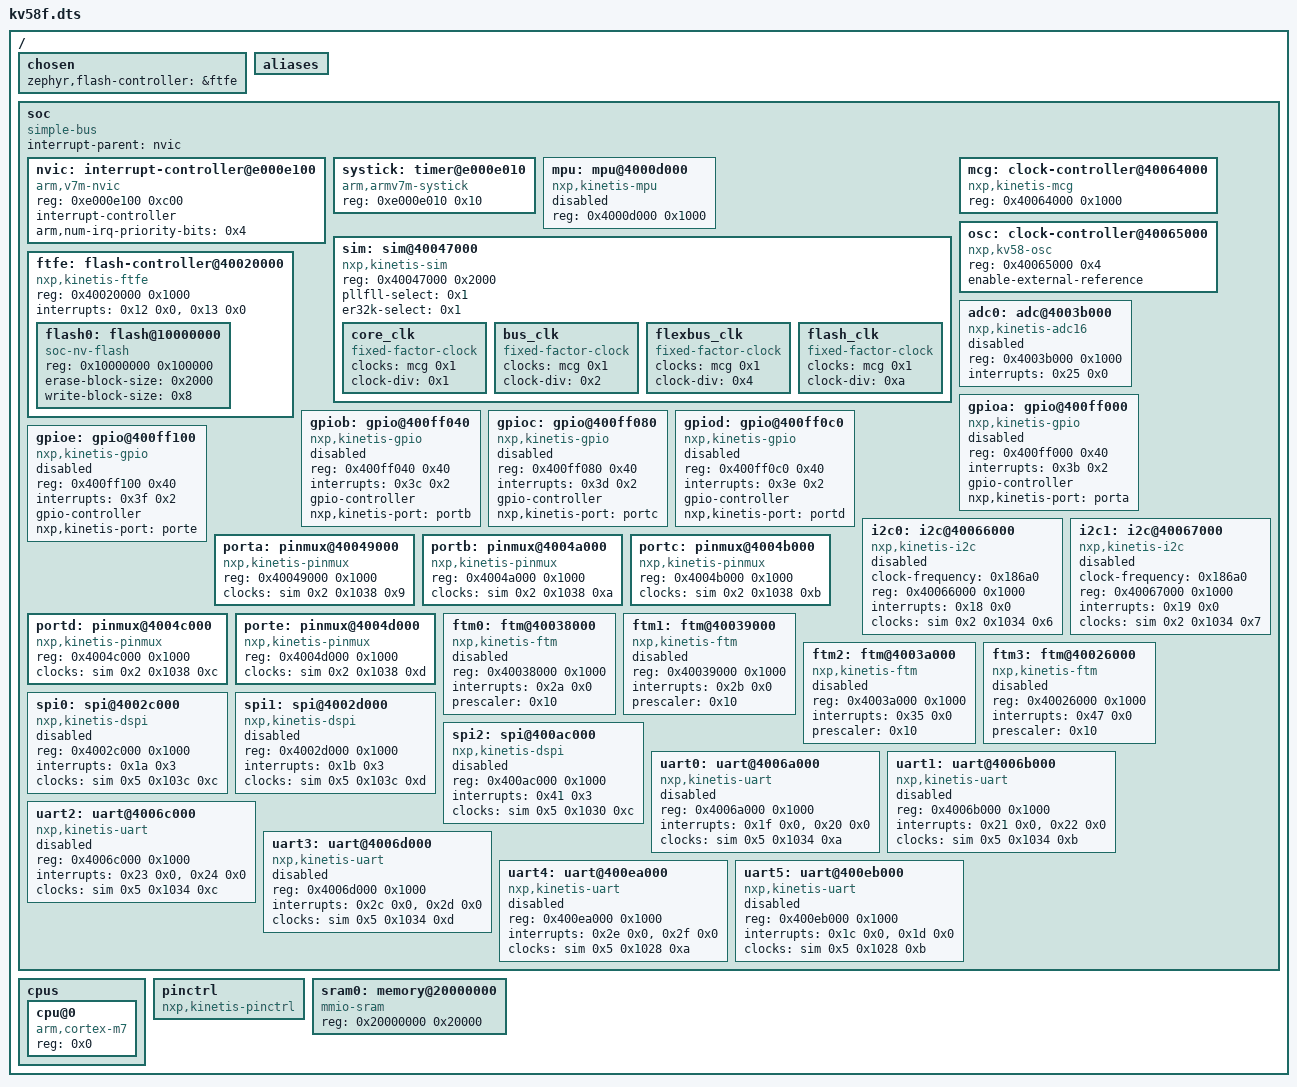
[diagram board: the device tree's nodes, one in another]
/dts-v1/;

/ {
	#address-cells = < 0x1 >;
	#size-cells = < 0x1 >;
	chosen {
		zephyr,flash-controller = &ftfe;
	};
	aliases {
	};
	soc {
		#address-cells = < 0x1 >;
		#size-cells = < 0x1 >;
		compatible = "simple-bus";
		interrupt-parent = < &nvic >;
		ranges;
		nvic: interrupt-controller@e000e100 {
			#address-cells = < 0x1 >;
			compatible = "arm,v7m-nvic";
			reg = < 0xe000e100 0xc00 >;
			interrupt-controller;
			#interrupt-cells = < 0x2 >;
			arm,num-irq-priority-bits = < 0x4 >;
			phandle = < 0x1 >;
		};
		systick: timer@e000e010 {
			compatible = "arm,armv7m-systick";
			reg = < 0xe000e010 0x10 >;
		};
		mpu: mpu@4000d000 {
			compatible = "nxp,kinetis-mpu";
			reg = < 0x4000d000 0x1000 >;
			status = "disabled";
		};
		sim: sim@40047000 {
			compatible = "nxp,kinetis-sim";
			reg = < 0x40047000 0x2000 >;
			#clock-cells = < 0x3 >;
			pllfll-select = < 0x1 >;
			er32k-select = < 0x1 >;
			phandle = < 0x8 >;
			core_clk {
				compatible = "fixed-factor-clock";
				clocks = < &mcg 0x1 >;
				clock-div = < 0x1 >;
				#clock-cells = < 0x0 >;
			};
			bus_clk {
				compatible = "fixed-factor-clock";
				clocks = < &mcg 0x1 >;
				clock-div = < 0x2 >;
				#clock-cells = < 0x0 >;
			};
			flexbus_clk {
				compatible = "fixed-factor-clock";
				clocks = < &mcg 0x1 >;
				clock-div = < 0x4 >;
				#clock-cells = < 0x0 >;
			};
			flash_clk {
				compatible = "fixed-factor-clock";
				clocks = < &mcg 0x1 >;
				clock-div = < 0xa >;
				#clock-cells = < 0x0 >;
			};
		};
		mcg: clock-controller@40064000 {
			compatible = "nxp,kinetis-mcg";
			reg = < 0x40064000 0x1000 >;
			#clock-cells = < 0x1 >;
			phandle = < 0x2 >;
		};
		osc: clock-controller@40065000 {
			compatible = "nxp,kv58-osc";
			reg = < 0x40065000 0x4 >;
			enable-external-reference;
		};
		ftfe: flash-controller@40020000 {
			compatible = "nxp,kinetis-ftfe";
			reg = < 0x40020000 0x1000 >;
			interrupts = < 0x12 0x0 >, < 0x13 0x0 >;
			interrupt-names = "command-complete", "read-collision";
			#address-cells = < 0x1 >;
			#size-cells = < 0x1 >;
			flash0: flash@10000000 {
				compatible = "soc-nv-flash";
				reg = < 0x10000000 0x100000 >;
				erase-block-size = < 0x2000 >;
				write-block-size = < 0x8 >;
			};
		};
		adc0: adc@4003b000 {
			compatible = "nxp,kinetis-adc16";
			reg = < 0x4003b000 0x1000 >;
			interrupts = < 0x25 0x0 >;
			status = "disabled";
			#io-channel-cells = < 0x1 >;
		};
		gpioa: gpio@400ff000 {
			compatible = "nxp,kinetis-gpio";
			status = "disabled";
			reg = < 0x400ff000 0x40 >;
			interrupts = < 0x3b 0x2 >;
			gpio-controller;
			#gpio-cells = < 0x2 >;
			nxp,kinetis-port = < &porta >;
		};
		gpiob: gpio@400ff040 {
			compatible = "nxp,kinetis-gpio";
			status = "disabled";
			reg = < 0x400ff040 0x40 >;
			interrupts = < 0x3c 0x2 >;
			gpio-controller;
			#gpio-cells = < 0x2 >;
			nxp,kinetis-port = < &portb >;
		};
		gpioc: gpio@400ff080 {
			compatible = "nxp,kinetis-gpio";
			status = "disabled";
			reg = < 0x400ff080 0x40 >;
			interrupts = < 0x3d 0x2 >;
			gpio-controller;
			#gpio-cells = < 0x2 >;
			nxp,kinetis-port = < &portc >;
		};
		gpiod: gpio@400ff0c0 {
			compatible = "nxp,kinetis-gpio";
			status = "disabled";
			reg = < 0x400ff0c0 0x40 >;
			interrupts = < 0x3e 0x2 >;
			gpio-controller;
			#gpio-cells = < 0x2 >;
			nxp,kinetis-port = < &portd >;
		};
		gpioe: gpio@400ff100 {
			compatible = "nxp,kinetis-gpio";
			status = "disabled";
			reg = < 0x400ff100 0x40 >;
			interrupts = < 0x3f 0x2 >;
			gpio-controller;
			#gpio-cells = < 0x2 >;
			nxp,kinetis-port = < &porte >;
		};
		i2c0: i2c@40066000 {
			compatible = "nxp,kinetis-i2c";
			clock-frequency = < 0x186a0 >;
			#address-cells = < 0x1 >;
			#size-cells = < 0x0 >;
			reg = < 0x40066000 0x1000 >;
			interrupts = < 0x18 0x0 >;
			clocks = < &sim 0x2 0x1034 0x6 >;
			status = "disabled";
		};
		i2c1: i2c@40067000 {
			compatible = "nxp,kinetis-i2c";
			clock-frequency = < 0x186a0 >;
			#address-cells = < 0x1 >;
			#size-cells = < 0x0 >;
			reg = < 0x40067000 0x1000 >;
			interrupts = < 0x19 0x0 >;
			clocks = < &sim 0x2 0x1034 0x7 >;
			status = "disabled";
		};
		porta: pinmux@40049000 {
			compatible = "nxp,kinetis-pinmux";
			reg = < 0x40049000 0x1000 >;
			clocks = < &sim 0x2 0x1038 0x9 >;
			phandle = < 0x3 >;
		};
		portb: pinmux@4004a000 {
			compatible = "nxp,kinetis-pinmux";
			reg = < 0x4004a000 0x1000 >;
			clocks = < &sim 0x2 0x1038 0xa >;
			phandle = < 0x4 >;
		};
		portc: pinmux@4004b000 {
			compatible = "nxp,kinetis-pinmux";
			reg = < 0x4004b000 0x1000 >;
			clocks = < &sim 0x2 0x1038 0xb >;
			phandle = < 0x5 >;
		};
		portd: pinmux@4004c000 {
			compatible = "nxp,kinetis-pinmux";
			reg = < 0x4004c000 0x1000 >;
			clocks = < &sim 0x2 0x1038 0xc >;
			phandle = < 0x6 >;
		};
		porte: pinmux@4004d000 {
			compatible = "nxp,kinetis-pinmux";
			reg = < 0x4004d000 0x1000 >;
			clocks = < &sim 0x2 0x1038 0xd >;
			phandle = < 0x7 >;
		};
		ftm0: ftm@40038000 {
			compatible = "nxp,kinetis-ftm";
			reg = < 0x40038000 0x1000 >;
			interrupts = < 0x2a 0x0 >;
			prescaler = < 0x10 >;
			status = "disabled";
		};
		ftm1: ftm@40039000 {
			compatible = "nxp,kinetis-ftm";
			reg = < 0x40039000 0x1000 >;
			interrupts = < 0x2b 0x0 >;
			prescaler = < 0x10 >;
			status = "disabled";
		};
		ftm2: ftm@4003a000 {
			compatible = "nxp,kinetis-ftm";
			reg = < 0x4003a000 0x1000 >;
			interrupts = < 0x35 0x0 >;
			prescaler = < 0x10 >;
			status = "disabled";
		};
		ftm3: ftm@40026000 {
			compatible = "nxp,kinetis-ftm";
			reg = < 0x40026000 0x1000 >;
			interrupts = < 0x47 0x0 >;
			prescaler = < 0x10 >;
			status = "disabled";
		};
		spi0: spi@4002c000 {
			compatible = "nxp,kinetis-dspi";
			reg = < 0x4002c000 0x1000 >;
			interrupts = < 0x1a 0x3 >;
			status = "disabled";
			clocks = < &sim 0x5 0x103c 0xc >;
			#address-cells = < 0x1 >;
			#size-cells = < 0x0 >;
		};
		spi1: spi@4002d000 {
			compatible = "nxp,kinetis-dspi";
			reg = < 0x4002d000 0x1000 >;
			interrupts = < 0x1b 0x3 >;
			status = "disabled";
			clocks = < &sim 0x5 0x103c 0xd >;
			#address-cells = < 0x1 >;
			#size-cells = < 0x0 >;
		};
		spi2: spi@400ac000 {
			compatible = "nxp,kinetis-dspi";
			reg = < 0x400ac000 0x1000 >;
			interrupts = < 0x41 0x3 >;
			status = "disabled";
			clocks = < &sim 0x5 0x1030 0xc >;
			#address-cells = < 0x1 >;
			#size-cells = < 0x0 >;
		};
		uart0: uart@4006a000 {
			compatible = "nxp,kinetis-uart";
			reg = < 0x4006a000 0x1000 >;
			interrupts = < 0x1f 0x0 >, < 0x20 0x0 >;
			interrupt-names = "status", "error";
			clocks = < &sim 0x5 0x1034 0xa >;
			status = "disabled";
		};
		uart1: uart@4006b000 {
			compatible = "nxp,kinetis-uart";
			reg = < 0x4006b000 0x1000 >;
			interrupts = < 0x21 0x0 >, < 0x22 0x0 >;
			interrupt-names = "status", "error";
			clocks = < &sim 0x5 0x1034 0xb >;
			status = "disabled";
		};
		uart2: uart@4006c000 {
			compatible = "nxp,kinetis-uart";
			reg = < 0x4006c000 0x1000 >;
			interrupts = < 0x23 0x0 >, < 0x24 0x0 >;
			interrupt-names = "status", "error";
			clocks = < &sim 0x5 0x1034 0xc >;
			status = "disabled";
		};
		uart3: uart@4006d000 {
			compatible = "nxp,kinetis-uart";
			reg = < 0x4006d000 0x1000 >;
			interrupts = < 0x2c 0x0 >, < 0x2d 0x0 >;
			interrupt-names = "status", "error";
			clocks = < &sim 0x5 0x1034 0xd >;
			status = "disabled";
		};
		uart4: uart@400ea000 {
			compatible = "nxp,kinetis-uart";
			reg = < 0x400ea000 0x1000 >;
			interrupts = < 0x2e 0x0 >, < 0x2f 0x0 >;
			interrupt-names = "status", "error";
			clocks = < &sim 0x5 0x1028 0xa >;
			status = "disabled";
		};
		uart5: uart@400eb000 {
			compatible = "nxp,kinetis-uart";
			reg = < 0x400eb000 0x1000 >;
			interrupts = < 0x1c 0x0 >, < 0x1d 0x0 >;
			interrupt-names = "status", "error";
			clocks = < &sim 0x5 0x1028 0xb >;
			status = "disabled";
		};
	};
	cpus {
		#address-cells = < 0x1 >;
		#size-cells = < 0x0 >;
		cpu@0 {
			device_type = "cpu";
			compatible = "arm,cortex-m7";
			reg = < 0x0 >;
		};
	};
	pinctrl: pinctrl {
		compatible = "nxp,kinetis-pinctrl";
		status = "okay";
	};
	sram0: memory@20000000 {
		compatible = "mmio-sram";
		reg = < 0x20000000 0x20000 >;
	};
};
